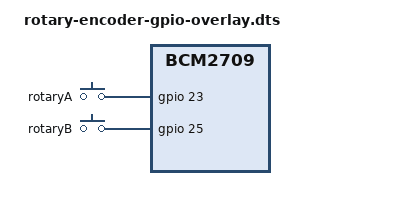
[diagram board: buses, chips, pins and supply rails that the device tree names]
// Device tree overlay for GPIO-based rotary encoder.
/dts-v1/;
/plugin/;
/ {
	compatible = "brcm,bcm2835", "brcm,bcm2708", "brcm,bcm2709";
	
	fragment@0 {
		// Configure the gpio pin controller
		target = <&gpio>;
		__overlay__ {
			pin_state: button_pins@0 {
				brcm,pins = <23 25>; 	// gpio 23 25
				brcm,function = <0 0>; 	// 0 = input, 1 = output
				brcm,pull = <1 1>; 	// 0 = none, 1 = pull down, 2 = pull up
			};
		};
	};

	fragment@1 {	
		target-path = "/";
		__overlay__ {
			key: rotary-gpio {
				compatible = "gpio-keys";
				#address-cells = <1>;
				#size-cells = <0>;
				rotaryA: rotaryA@23 {
					label = "rotaryA";
					linux,code = <59>;      // F1 Key
					gpios = <&gpio 23 0>;   // GPIO 23				
					wakeup-source;					
				};
        			rotaryB: rotaryB@25 {				
          				label = "rotaryB";
					linux,code = <60>;      // F2 Key
					gpios = <&gpio 25 0>;   // GPIO 25					
					wakeup-source;					
        			};
			};
		};
	};
	
	__overrides__ {
		gpioA =      	<&rotaryA>,"gpios:4",
			     	<&pin_state>,"brcm,pins:0",
		              	/* modify reg values to allow multiple instantiation */
			     	<&key>,"reg:0",		            
		             	<&pin_state>,"reg:0";
		gpioB =	     	<&rotaryB>,"gpios:4",		             
		             	<&pin_state>,"brcm,pins:4";		             
		labelA =     	<&rotaryA>,"label";
		labelB =     	<&rotaryB>,"label";
		keycodeA =   	<&rotaryA>,"linux,code:0";
		keycodeB =   	<&rotaryB>,"linux,code:0";
		gpio_pullA = 	<&pin_state>,"brcm,pull:0";
		gpio_pullB = 	<&pin_state>,"brcm,pull:4";		
		active_lowA =	<&rotaryA>,"gpios:8";
		active_lowB =	<&rotaryB>,"gpios:8";
	};
};
